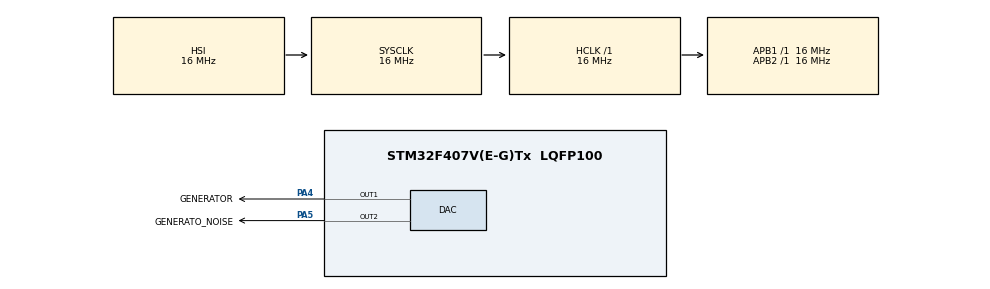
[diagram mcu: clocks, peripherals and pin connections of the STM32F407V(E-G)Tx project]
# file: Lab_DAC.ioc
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DAC.DAC_Trigger=DAC_TRIGGER_T6_TRGO
DAC.DAC_Trigger2=DAC_TRIGGER_T5_TRGO
DAC.WaveGeneration2=NoiseWaveGeneration
Dma.DAC1.0.Direction=DMA_MEMORY_TO_PERIPH
Dma.DAC1.0.FIFOMode=DMA_FIFOMODE_DISABLE
Dma.DAC1.0.Instance=DMA1_Stream5
Dma.DAC1.0.MemDataAlignment=DMA_MDATAALIGN_HALFWORD
Dma.DAC1.0.MemInc=DMA_MINC_ENABLE
Dma.DAC1.0.Mode=DMA_NORMAL
Dma.DAC1.0.PeriphDataAlignment=DMA_PDATAALIGN_HALFWORD
Dma.DAC1.0.PeriphInc=DMA_PINC_DISABLE
Dma.DAC1.0.Priority=DMA_PRIORITY_LOW
Dma.Request0=DAC1
Mcu.Family=STM32F4
Mcu.Name=STM32F407V(E-G)Tx
Mcu.Package=LQFP100
NVIC.DMA1_Stream5_IRQn=true\:0\:0\:false\:false\:true\:false\:true\:true
NVIC.PriorityGroup=NVIC_PRIORITYGROUP_4
PA4.GPIO_Label=GENERATOR
PA4.Signal=COMP_DAC1_group
PA5.GPIO_Label=GENERATO_NOISE
PA5.Signal=COMP_DAC2_group
ProjectManager.HeapSize=0x200
ProjectManager.StackSize=0x400
ProjectManager.TargetToolchain=MDK-ARM V5.32
RCC.AHBFreq_Value=16000000
RCC.APB1Freq_Value=16000000
RCC.APB2Freq_Value=16000000
RCC.CortexFreq_Value=16000000
RCC.HSE_VALUE=25000000
RCC.HSI_VALUE=16000000
RCC.LSE_VALUE=32768
RCC.SYSCLKFreq_VALUE=16000000
RCC.VCOOutputFreq_Value=192000000
SH.COMP_DAC1_group.0=DAC_OUT1,DAC_OUT1
SH.COMP_DAC2_group.0=DAC_OUT2,DAC_OUT2
TIM5.Channel-PWM\ Generation1\ No\ Output=TIM_CHANNEL_1
TIM5.Period=1000-1
TIM5.Prescaler=16-1
TIM5.Pulse-PWM\ Generation1\ No\ Output=500
TIM5.TIM_MasterOutputTrigger=TIM_TRGO_OC1REF
TIM6.Period=1000-1
TIM6.Prescaler=16-1
TIM6.TIM_MasterOutputTrigger=TIM_TRGO_UPDATE
VP_TIM5_VS_ClockSourceINT.Mode=Internal
VP_TIM5_VS_no_output1.Mode=PWM Generation1 No Output
VP_TIM6_VS_ClockSourceINT.Mode=Enable_Timer
board=custom

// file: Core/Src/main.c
/* USER CODE BEGIN Header */
/**
  ******************************************************************************
  * @file           : main.c
  * @brief          : Main program body
  ******************************************************************************
  * @attention
  *
  * Copyright (c) 2022 STMicroelectronics.
  * All rights reserved.
  *
  * This software is licensed under terms that can be found in the LICENSE file
  * in the root directory of this software component.
  * If no LICENSE file comes with this software, it is provided AS-IS.
  *
  ******************************************************************************
  */
/* USER CODE END Header */
#include "main.h"
#include "dac.h"
#include "dma.h"
#include "tim.h"
#include "gpio.h"

/* USER CODE BEGIN PM */
#define SIZE_BUFF 50
#define DAC_MAX_VALUE 4095
/* USER CODE END PM */

/* USER CODE BEGIN PV */
uint32_t dac_buff[SIZE_BUFF] = {0};
/* USER CODE END PV */

void SystemClock_Config(void);

int main(void)
{

  /* MCU Configuration--------------------------------------------------------*/

  /* Reset of all peripherals, Initializes the Flash interface and the Systick. */
  HAL_Init();

  /* Configure the system clock */
  SystemClock_Config();

  /* Initialize all configured peripherals */
  MX_GPIO_Init();
  MX_DMA_Init();
  MX_DAC_Init();
  MX_TIM5_Init();
  MX_TIM6_Init();
  /* USER CODE BEGIN 2 */
  uint8_t x = 0;
  for (x = 0; x < (SIZE_BUFF / 2); x ++)
  {
    dac_buff[x] = (uint32_t)((float)DAC_MAX_VALUE / (SIZE_BUFF / 2) * x);
    dac_buff[x + SIZE_BUFF / 2] = DAC_MAX_VALUE - dac_buff[x];
  }
  __HAL_TIM_SET_AUTORELOAD(&htim6, 200);
//  HAL_DAC_SetValue(&hdac, DAC_CHANNEL_1, DAC_ALIGN_12B_R, 0x003F);
//  HAL_DAC_Start(&hdac, DAC_CHANNEL_1);
  HAL_DAC_Start_DMA(&hdac, DAC_CHANNEL_1, &dac_buff[0], SIZE_BUFF, DAC_ALIGN_12B_R);
  HAL_TIM_Base_Start(&htim6);

  HAL_DAC_Start(&hdac, DAC_CHANNEL_2);
  HAL_TIM_Base_Start(&htim5);
  HAL_TIM_PWM_Start(&htim5, TIM_CHANNEL_1);
  /* USER CODE END 2 */

  /* Infinite loop */
  while (1)
  {

  }
}

void SystemClock_Config(void)
{
  RCC_OscInitTypeDef RCC_OscInitStruct = {0};
  RCC_ClkInitTypeDef RCC_ClkInitStruct = {0};

  /** Configure the main internal regulator output voltage
  */
  __HAL_RCC_PWR_CLK_ENABLE();
  __HAL_PWR_VOLTAGESCALING_CONFIG(PWR_REGULATOR_VOLTAGE_SCALE1);

  /** Initializes the RCC Oscillators according to the specified parameters
  * in the RCC_OscInitTypeDef structure.
  */
  RCC_OscInitStruct.OscillatorType = RCC_OSCILLATORTYPE_HSI;
  RCC_OscInitStruct.HSIState = RCC_HSI_ON;
  RCC_OscInitStruct.HSICalibrationValue = RCC_HSICALIBRATION_DEFAULT;
  RCC_OscInitStruct.PLL.PLLState = RCC_PLL_NONE;
  if (HAL_RCC_OscConfig(&RCC_OscInitStruct) != HAL_OK)
  {
    Error_Handler();
  }

  /** Initializes the CPU, AHB and APB buses clocks
  */
  RCC_ClkInitStruct.ClockType = RCC_CLOCKTYPE_HCLK|RCC_CLOCKTYPE_SYSCLK
                              |RCC_CLOCKTYPE_PCLK1|RCC_CLOCKTYPE_PCLK2;
  RCC_ClkInitStruct.SYSCLKSource = RCC_SYSCLKSOURCE_HSI;
  RCC_ClkInitStruct.AHBCLKDivider = RCC_SYSCLK_DIV1;
  RCC_ClkInitStruct.APB1CLKDivider = RCC_HCLK_DIV1;
  RCC_ClkInitStruct.APB2CLKDivider = RCC_HCLK_DIV1;

  if (HAL_RCC_ClockConfig(&RCC_ClkInitStruct, FLASH_LATENCY_0) != HAL_OK)
  {
    Error_Handler();
  }
}

void Error_Handler(void)
{
  __disable_irq();
  while (1)
  {
  }
}
